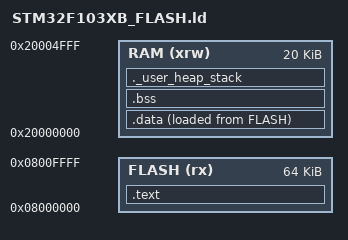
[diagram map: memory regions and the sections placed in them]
MEMORY
{
  FLASH (rx)  : ORIGIN = 0x08000000, LENGTH = 64K
  RAM   (xrw) : ORIGIN = 0x20000000, LENGTH = 20K
}

_estack = ORIGIN(RAM) + LENGTH(RAM);
_Min_Heap_Size  = 0x200;
_Min_Stack_Size = 0x400;

ENTRY(Reset_Handler)

SECTIONS
{
  .text : ALIGN(4)
  {
    KEEP(*(.isr_vector))
    *(.text*)
    *(.rodata*)
    . = ALIGN(4);
    _etext = .;
  } > FLASH

  .data : ALIGN(4)
  {
    _sdata = .;
    *(.data*)
    . = ALIGN(4);
    _edata = .;
  } > RAM AT > FLASH

  _sidata = LOADADDR(.data);

  .bss : ALIGN(4)
  {
    _sbss = .;
    *(.bss*)
    *(COMMON)
    . = ALIGN(4);
    _ebss = .;
  } > RAM

  ._user_heap_stack : ALIGN(8)
  {
    . = ALIGN(8);
    PROVIDE ( end = . );
    PROVIDE ( _end = . );
    . = . + _Min_Heap_Size;
    . = . + _Min_Stack_Size;
    . = ALIGN(8);
  } > RAM
}
